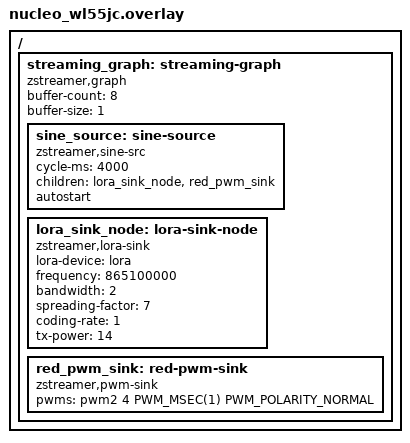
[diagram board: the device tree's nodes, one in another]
/*
 * Copyright (c) 2026 sharonthecreator
 * SPDX-License-Identifier: Apache-2.0
 *
 * Sine wave generator to LoRa transmitter + red LED on Nucleo WL55JC.
 */

/ {
	streaming_graph: streaming-graph {
		compatible = "zstreamer,graph";
		buffer-count = <8>;
		buffer-size = <1>;

		sine_source: sine-source {
			compatible = "zstreamer,sine-src";
			cycle-ms = <4000>;
			children = <&lora_sink_node &red_pwm_sink>;
			autostart;
		};

		lora_sink_node: lora-sink-node {
			compatible = "zstreamer,lora-sink";
			lora-device = <&lora>;
			frequency = <865100000>;
			bandwidth = <2>;
			spreading-factor = <7>;
			coding-rate = <1>;
			tx-power = <14>;
		};

		red_pwm_sink: red-pwm-sink {
			compatible = "zstreamer,pwm-sink";
			pwms = <&pwm2 4 PWM_MSEC(1) PWM_POLARITY_NORMAL>;
		};
	};
};
